# AVR128DA64S register map
Vendor: Atmel; File version: 1.0
CPU: other r0p0, little endian, no MPU, no FPU, 4 interrupt priority bits
Registers are 8-bit, read-write, reset 0x0 unless marked. A register's access mark holds for its fields unless they carry their own. Offsets are from the block's base; [hi:lo] are bit positions; 'fields as' and 'values as' point back to an identical list.

## TCD0 — Timer Counter D
Base 0x00800B80
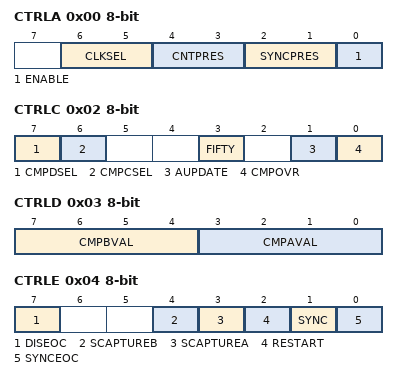
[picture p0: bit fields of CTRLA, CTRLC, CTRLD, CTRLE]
0x00 CTRLA — Control A
  [6:5] CLKSEL — Clock select
    0=OSCHF (Internal High-Frequency Oscillator); 1=PLL; 2=EXTCLK (External Clock); 3=CLKPER (Peripheral Clock)
  [4:3] CNTPRES — Counter prescaler
    0=DIV1 (Sync clock divided by 1); 1=DIV4 (Sync clock divided by 4); 2=DIV32 (Sync clock divided by 32)
  [2:1] SYNCPRES — Synchronization prescaler
    0=DIV1 (Selected clock source divided by 1); 1=DIV2 (Selected clock source divided by 2); 2=DIV4 (Selected clock source divided by 4); 3=DIV8 (Selected clock source divided by 8)
  [0] ENABLE
0x01 CTRLB — Control B
  [1:0] WGMODE — Waveform generation mode
    0=ONERAMP (One ramp mode); 1=TWORAMP (Two ramp mode); 2=FOURRAMP (Four ramp mode); 3=DS (Dual slope mode)
0x02 CTRLC — Control C
  [7] CMPDSEL — Compare D output select
    0=PWMA (PWM A output); 1=PWMB (PWM B output)
  [6] CMPCSEL — Compare C output select
    0=PWMA (PWM A output); 1=PWMB (PWM B output)
  [3] FIFTY — Fifty percent waveform
  [1] AUPDATE — Auto update
  [0] CMPOVR — Compare output value override
0x03 CTRLD — Control D
  [7:4] CMPBVAL — Compare B value
  [3:0] CMPAVAL — Compare A value
0x04 CTRLE — Control E
  [7] DISEOC — Disable at end of cycle
  [4] SCAPTUREB — Software Capture B Strobe
  [3] SCAPTUREA — Software Capture A Strobe
  [2] RESTART — Restart strobe
  [1] SYNC — synchronize strobe
  [0] SYNCEOC — Synchronize end of cycle strobe
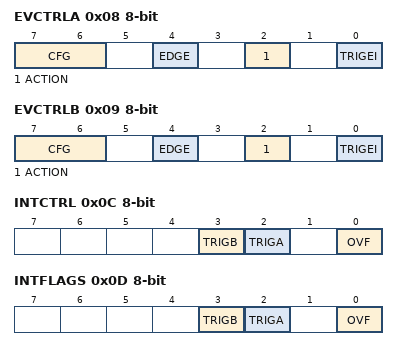
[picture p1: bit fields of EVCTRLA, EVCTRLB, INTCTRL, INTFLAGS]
0x08 EVCTRLA
  [7:6] CFG — Event config
    0=NEITHER (Neither Filter nor Asynchronous Event is enabled); 1=FILTER (Input Capture Noise Cancellation Filter enabled); 2=ASYNC (Asynchronous Event output qualification enabled)
  [4] EDGE — Edge select
    0=FALL_LOW (The falling edge or low level of event generates retrigger or fault action); 1=RISE_HIGH (The rising edge or high level of event generates retrigger or fault action)
  [2] ACTION — Event action
    0=FAULT (Event trigger a fault); 1=CAPTURE (Event trigger a fault and capture)
  [0] TRIGEI — Trigger event enable
0x09 EVCTRLB
  fields as EVCTRLA
0x0C INTCTRL — Interrupt Control
  [3] TRIGB — Trigger B interrupt enable
  [2] TRIGA — Trigger A interrupt enable
  [0] OVF — Overflow interrupt enable
0x0D INTFLAGS — Interrupt Flags
  fields as INTCTRL
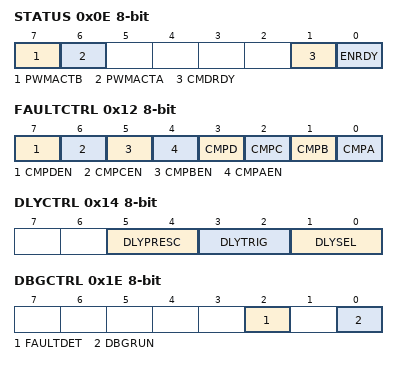
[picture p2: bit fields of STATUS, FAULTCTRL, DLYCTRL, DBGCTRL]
0x0E STATUS
  [7] PWMACTB — PWM activity on B
  [6] PWMACTA — PWM activity on A
  [1] CMDRDY ro — Command ready
  [0] ENRDY ro — Enable ready
0x10 INPUTCTRLA — Input Control A
  [3:0] INPUTMODE
    0=NONE (Input has no actions); 1=JMPWAIT (Stop output, jump to opposite compare cycle and wait); 2=EXECWAIT (Stop output, execute opposite compare cycle and wait); 3=EXECFAULT (stop output, execute opposite compare cycle while fault active); 4=FREQ (Stop all outputs, maintain frequency); 5=EXECDT (Stop all outputs, execute dead time while fault active); 6=WAIT (Stop all outputs, jump to next compare cycle and wait); 7=WAITSW (Stop all outputs, wait for software action); 8=EDGETRIG (Stop output on edge, jump to next compare cycle); 9=EDGETRIGFREQ (Stop output on edge, maintain frequency); 10=LVLTRIGFREQ (Stop output at level, maintain frequency)
0x11 INPUTCTRLB — Input Control B
  fields as INPUTCTRLA
0x12 FAULTCTRL — Fault Control
  [7] CMPDEN — Compare D enable
  [6] CMPCEN — Compare C enable
  [5] CMPBEN — Compare B enable
  [4] CMPAEN — Compare A enable
  [3] CMPD — Compare D vaule
  [2] CMPC — Compare C value
  [1] CMPB — Compare B value
  [0] CMPA — Compare A value
0x14 DLYCTRL — Delay Control
  [5:4] DLYPRESC — Delay prescaler
    0=DIV1 (No prescaling); 1=DIV2 (Prescale with 2); 2=DIV4 (Prescale with 4); 3=DIV8 (Prescale with 8)
  [3:2] DLYTRIG — Delay trigger
    0=CMPASET (Compare A set); 1=CMPACLR (Compare A clear); 2=CMPBSET (Compare B set); 3=CMPBCLR (Compare B clear)
  [1:0] DLYSEL — Delay select
    0=OFF (No delay); 1=INBLANK (Input blanking enabled); 2=EVENT (Event delay enabled)
0x15 DLYVAL — Delay value
0x18 DITCTRL — Dither Control A
  [1:0] DITHERSEL — Dither select
    0=ONTIMEB (On-time ramp B); 1=ONTIMEAB (On-time ramp A and B); 2=DEADTIMEB (Dead-time rampB); 3=DEADTIMEAB (Dead-time ramp A and B)
0x19 DITVAL — Dither value
  [3:0] DITHER
0x1E DBGCTRL — Debug Control
  [2] FAULTDET — Fault detection
  [0] DBGRUN — Debug run
0x22 CAPTUREA 16-bit ro (reset mask 0xFF)
  [11:0] CAPTUREA
0x24 CAPTUREB 16-bit ro (reset mask 0xFF)
  [11:0] CAPTUREB
0x28 CMPASET 16-bit (reset mask 0xFF) — Compare A Set
  [11:0] CMPASET
0x2A CMPACLR 16-bit (reset mask 0xFF) — Compare A Clear
  [11:0] CMPACLR
0x2C CMPBSET 16-bit (reset mask 0xFF) — Compare B Set
  [11:0] CMPBSET
0x2E CMPBCLR 16-bit (reset mask 0xFF) — Compare B Clear
  [11:0] COMPBCLR
